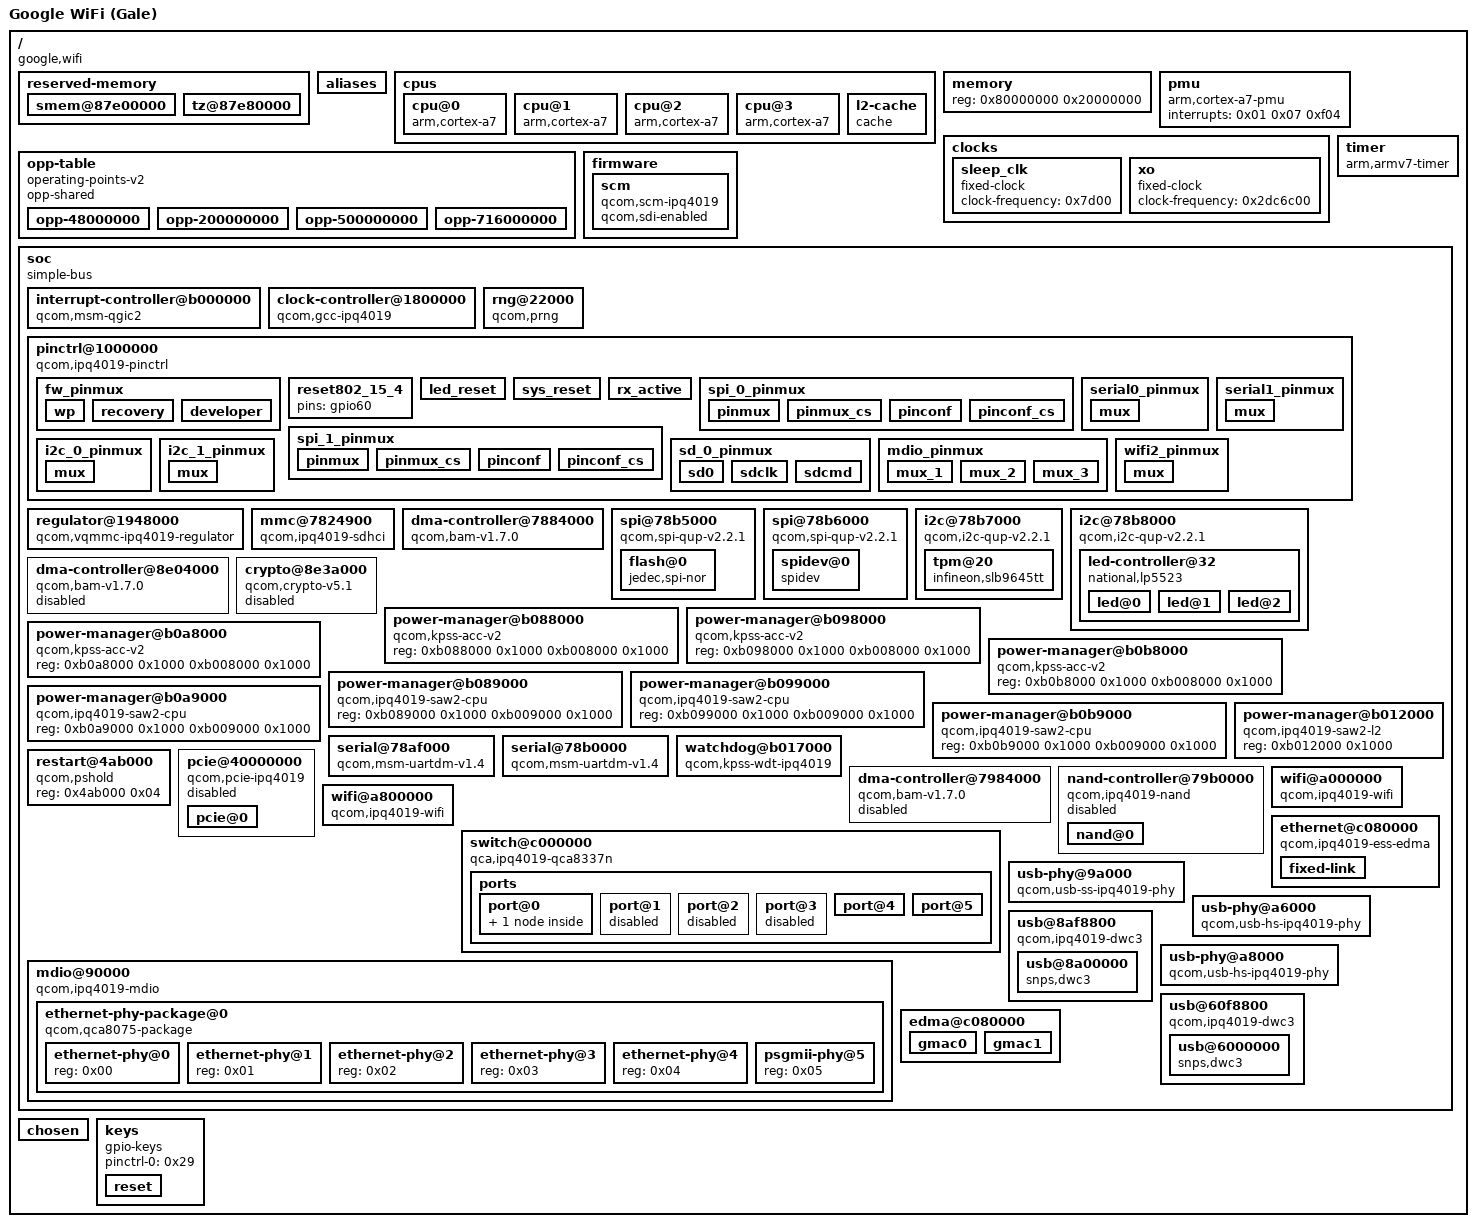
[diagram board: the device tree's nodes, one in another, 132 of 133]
/dts-v1/;

/ {
	#address-cells = <0x01>;
	#size-cells = <0x01>;
	model = "Google WiFi (Gale)";
	compatible = "google,wifi\0google,gale-v2\0qcom,ipq4019";
	interrupt-parent = <0x01>;

	reserved-memory {
		#address-cells = <0x01>;
		#size-cells = <0x01>;
		ranges;

		smem@87e00000 {
			reg = <0x87e00000 0x80000>;
			no-map;
		};

		tz@87e80000 {
			reg = <0x87e80000 0x180000>;
			no-map;
		};
	};

	aliases {
		spi0 = "/soc/spi@78b5000";
		spi1 = "/soc/spi@78b6000";
		i2c0 = "/soc/i2c@78b7000";
		i2c1 = "/soc/i2c@78b8000";
		ethernet0 = "/soc/ethernet@c080000";
		label-mac-device = "/soc/edma@c080000/gmac0";
		led-boot = "/soc/i2c@78b8000/led-controller@32/led@2";
		led-failsafe = "/soc/i2c@78b8000/led-controller@32/led@0";
		led-running = "/soc/i2c@78b8000/led-controller@32/led@2";
		led-upgrade = "/soc/i2c@78b8000/led-controller@32/led@0";
	};

	cpus {
		#address-cells = <0x01>;
		#size-cells = <0x00>;

		cpu@0 {
			device_type = "cpu";
			compatible = "arm,cortex-a7";
			enable-method = "qcom,kpss-acc-v2";
			next-level-cache = <0x02>;
			qcom,acc = <0x03>;
			qcom,saw = <0x04>;
			reg = <0x00>;
			clocks = <0x05 0x09>;
			clock-frequency = <0x00>;
			clock-latency = <0x3e800>;
			operating-points-v2 = <0x06>;
		};

		cpu@1 {
			device_type = "cpu";
			compatible = "arm,cortex-a7";
			enable-method = "qcom,kpss-acc-v2";
			next-level-cache = <0x02>;
			qcom,acc = <0x07>;
			qcom,saw = <0x08>;
			reg = <0x01>;
			clocks = <0x05 0x09>;
			clock-frequency = <0x00>;
			clock-latency = <0x3e800>;
			operating-points-v2 = <0x06>;
		};

		cpu@2 {
			device_type = "cpu";
			compatible = "arm,cortex-a7";
			enable-method = "qcom,kpss-acc-v2";
			next-level-cache = <0x02>;
			qcom,acc = <0x09>;
			qcom,saw = <0x0a>;
			reg = <0x02>;
			clocks = <0x05 0x09>;
			clock-frequency = <0x00>;
			clock-latency = <0x3e800>;
			operating-points-v2 = <0x06>;
		};

		cpu@3 {
			device_type = "cpu";
			compatible = "arm,cortex-a7";
			enable-method = "qcom,kpss-acc-v2";
			next-level-cache = <0x02>;
			qcom,acc = <0x0b>;
			qcom,saw = <0x0c>;
			reg = <0x03>;
			clocks = <0x05 0x09>;
			clock-frequency = <0x00>;
			clock-latency = <0x3e800>;
			operating-points-v2 = <0x06>;
		};

		l2-cache {
			compatible = "cache";
			cache-level = <0x02>;
			cache-unified;
			qcom,saw = <0x0d>;
			phandle = <0x02>;
		};
	};

	opp-table {
		compatible = "operating-points-v2";
		opp-shared;
		phandle = <0x06>;

		opp-48000000 {
			opp-hz = <0x00 0x2dc6c00>;
			clock-latency-ns = <0x3e800>;
		};

		opp-200000000 {
			opp-hz = <0x00 0xbebc200>;
			clock-latency-ns = <0x3e800>;
		};

		opp-500000000 {
			opp-hz = <0x00 0x1dcd6500>;
			clock-latency-ns = <0x3e800>;
		};

		opp-716000000 {
			opp-hz = <0x00 0x2aad4b00>;
			clock-latency-ns = <0x3e800>;
		};
	};

	memory {
		device_type = "memory";
		reg = <0x80000000 0x20000000>;
	};

	pmu {
		compatible = "arm,cortex-a7-pmu";
		interrupts = <0x01 0x07 0xf04>;
	};

	clocks {

		sleep_clk {
			compatible = "fixed-clock";
			clock-frequency = <0x7d00>;
			#clock-cells = <0x00>;
			phandle = <0x0f>;
		};

		xo {
			compatible = "fixed-clock";
			clock-frequency = <0x2dc6c00>;
			#clock-cells = <0x00>;
			phandle = <0x0e>;
		};
	};

	firmware {

		scm {
			compatible = "qcom,scm-ipq4019\0qcom,scm";
			qcom,sdi-enabled;
		};
	};

	timer {
		compatible = "arm,armv7-timer";
		interrupts = <0x01 0x02 0xf08 0x01 0x03 0xf08 0x01 0x04 0xf08 0x01 0x01 0xf08>;
		clock-frequency = <0x2dc6c00>;
		always-on;
	};

	soc {
		#address-cells = <0x01>;
		#size-cells = <0x01>;
		ranges;
		compatible = "simple-bus";

		interrupt-controller@b000000 {
			compatible = "qcom,msm-qgic2";
			interrupt-controller;
			#interrupt-cells = <0x03>;
			reg = <0xb000000 0x1000 0xb002000 0x1000>;
			phandle = <0x01>;
		};

		clock-controller@1800000 {
			compatible = "qcom,gcc-ipq4019";
			#clock-cells = <0x01>;
			#reset-cells = <0x01>;
			reg = <0x1800000 0x60000>;
			clocks = <0x0e 0x0f>;
			clock-names = "xo\0sleep_clk";
			phandle = <0x05>;
		};

		rng@22000 {
			compatible = "qcom,prng";
			reg = <0x22000 0x140>;
			clocks = <0x05 0x2b>;
			clock-names = "core";
			status = "okay";
		};

		pinctrl@1000000 {
			compatible = "qcom,ipq4019-pinctrl";
			reg = <0x1000000 0x300000>;
			gpio-controller;
			gpio-ranges = <0x10 0x00 0x00 0x64>;
			#gpio-cells = <0x02>;
			interrupt-controller;
			#interrupt-cells = <0x02>;
			interrupts = <0x00 0xd0 0x04>;
			gpio-line-names = <0x00 0x00 0x00 0x00 0x00 0x00 0x00 0x00 0x00 0x00 0x00 0x00 0x00 0x41505f 0x464c4153 0x485f5750 0x5f4c0000 0x5245 0x434f5645 0x52595f53 0x575f4c00>;
			phandle = <0x10>;

			fw_pinmux {
				phandle = <0x29>;

				wp {
					pins = "gpio53";
					output-low;
				};

				recovery {
					pins = "gpio57";
					function = "gpio";
					bias-none;
				};

				developer {
					pins = "gpio41";
					bias-none;
				};
			};

			reset802_15_4 {
				pins = "gpio60";
			};

			led_reset {
				pins = "gpio22";
				output-high;
			};

			sys_reset {
				pins = "gpio19";
				output-high;
			};

			rx_active {
				pins = "gpio43";
				bias-pull,down;
			};

			spi_0_pinmux {
				phandle = <0x14>;

				pinmux {
					function = "blsp_spi0";
					pins = "gpio13\0gpio14\0gpio15";
				};

				pinmux_cs {
					function = "gpio";
					pins = "gpio12";
				};

				pinconf {
					pins = "gpio13\0gpio14\0gpio15";
					drive-strength = <0x0c>;
					bias-disable;
				};

				pinconf_cs {
					pins = "gpio12";
					drive-strength = <0x02>;
					bias-disable;
					output-high;
				};
			};

			spi_1_pinmux {
				phandle = <0x15>;

				pinmux {
					function = "blsp_spi1";
					pins = "gpio44\0gpio46\0gpio47";
				};

				pinmux_cs {
					function = "gpio";
					pins = "gpio45";
				};

				pinconf {
					pins = "gpio44\0gpio46\0gpio47";
					drive-strength = <0x0c>;
					bias-disable;
				};

				pinconf_cs {
					pins = "gpio45";
					drive-strength = <0x02>;
					bias-disable;
					output-high;
				};
			};

			serial0_pinmux {
				phandle = <0x19>;

				mux {
					pins = "gpio16\0gpio17";
					function = "blsp_uart0";
					bias-disable;
				};
			};

			serial1_pinmux {
				phandle = <0x1a>;

				mux {
					pins = "gpio8\0gpio9\0gpio10\0gpio11";
					function = "blsp_uart1";
					bias-disable;
				};
			};

			i2c_0_pinmux {
				phandle = <0x16>;

				mux {
					pins = "gpio20\0gpio21";
					function = "blsp_i2c0";
					drive-open-drain;
				};
			};

			i2c_1_pinmux {
				phandle = <0x17>;

				mux {
					pins = "gpio34\0gpio35";
					function = "blsp_i2c1";
					drive-open-drain;
				};
			};

			sd_0_pinmux {
				phandle = <0x11>;

				sd0 {
					pins = "gpio23\0gpio24\0gpio25\0gpio26\0gpio29\0gpio30\0gpio31\0gpio32";
					function = "sdio";
					drive-strength = <0x0a>;
					bias-pull-up;
					pull-up-res = <0x00>;
				};

				sdclk {
					pins = "gpio27";
					function = "sdio";
					drive-strength = <0x02>;
					bias-pull-up;
					pull-up-res = <0x00>;
				};

				sdcmd {
					pins = "gpio28";
					function = "sdio";
					drive-strength = <0x0a>;
					bias-pull-up;
					pull-up-res = <0x00>;
				};
			};

			mdio_pinmux {
				phandle = <0x25>;

				mux_1 {
					pins = "gpio6";
					function = "mdio";
					bias-disable;
				};

				mux_2 {
					pins = "gpio7";
					function = "mdc";
					bias-disable;
				};

				mux_3 {
					pins = "gpio40";
					function = "gpio";
					bias-disable;
					output-high;
				};
			};

			wifi2_pinmux {
				phandle = <0x1c>;

				mux {
					pins = "gpio58";
					output-low;
				};
			};
		};

		regulator@1948000 {
			compatible = "qcom,vqmmc-ipq4019-regulator";
			reg = <0x1948000 0x04>;
			regulator-name = "vqmmc";
			regulator-min-microvolt = <0x16e360>;
			regulator-max-microvolt = <0x2dc6c0>;
			regulator-always-on;
			status = "okay";
			phandle = <0x12>;
		};

		mmc@7824900 {
			compatible = "qcom,ipq4019-sdhci\0qcom,sdhci-msm-v4";
			reg = <0x7824900 0x11c 0x7824000 0x800>;
			reg-names = "hc\0core";
			interrupts = <0x00 0x7b 0x04 0x00 0x8a 0x04>;
			interrupt-names = "hc_irq\0pwr_irq";
			bus-width = <0x08>;
			clocks = <0x05 0x2e 0x05 0x2f 0x0e>;
			clock-names = "iface\0core\0xo";
			status = "okay";
			pinctrl-0 = <0x11>;
			pinctrl-names = "default";
			clock-frequency = <0xb71b000>;
			vqmmc-supply = <0x12>;
			non-removable;
		};

		dma-controller@7884000 {
			compatible = "qcom,bam-v1.7.0";
			reg = <0x7884000 0x23000>;
			interrupts = <0x00 0xee 0x04>;
			clocks = <0x05 0x15>;
			clock-names = "bam_clk";
			#dma-cells = <0x01>;
			qcom,ee = <0x00>;
			status = "okay";
			phandle = <0x13>;
		};

		spi@78b5000 {
			compatible = "qcom,spi-qup-v2.2.1";
			reg = <0x78b5000 0x600>;
			interrupts = <0x00 0x5f 0x04>;
			clocks = <0x05 0x17 0x05 0x15>;
			clock-names = "core\0iface";
			#address-cells = <0x01>;
			#size-cells = <0x00>;
			dmas = <0x13 0x04 0x13 0x05>;
			dma-names = "tx\0rx";
			status = "okay";
			pinctrl-0 = <0x14>;
			pinctrl-names = "default";
			cs-gpios = <0x10 0x0c 0x01>;

			flash@0 {
				compatible = "jedec,spi-nor";
				reg = <0x00>;
				spi-max-frequency = <0x16e3600>;
			};
		};

		spi@78b6000 {
			compatible = "qcom,spi-qup-v2.2.1";
			reg = <0x78b6000 0x600>;
			interrupts = <0x00 0x60 0x04>;
			clocks = <0x05 0x19 0x05 0x15>;
			clock-names = "core\0iface";
			#address-cells = <0x01>;
			#size-cells = <0x00>;
			dmas = <0x13 0x06 0x13 0x07>;
			dma-names = "tx\0rx";
			status = "okay";
			pinctrl-0 = <0x15>;
			pinctrl-names = "default";
			cs-gpios = <0x10 0x2d 0x01>;

			spidev@0 {
				compatible = "spidev";
				reg = <0x00>;
				spi-max-frequency = <0x16e3600>;
			};
		};

		i2c@78b7000 {
			compatible = "qcom,i2c-qup-v2.2.1";
			reg = <0x78b7000 0x600>;
			interrupts = <0x00 0x61 0x04>;
			clocks = <0x05 0x16 0x05 0x15>;
			clock-names = "core\0iface";
			#address-cells = <0x01>;
			#size-cells = <0x00>;
			dmas = <0x13 0x08 0x13 0x09>;
			dma-names = "tx\0rx";
			status = "okay";
			pinctrl-0 = <0x16>;
			pinctrl-names = "default";

			tpm@20 {
				compatible = "infineon,slb9645tt";
				reg = <0x20>;
				powered-while-suspended;
			};
		};

		i2c@78b8000 {
			compatible = "qcom,i2c-qup-v2.2.1";
			reg = <0x78b8000 0x600>;
			interrupts = <0x00 0x62 0x04>;
			clocks = <0x05 0x18 0x05 0x15>;
			clock-names = "core\0iface";
			#address-cells = <0x01>;
			#size-cells = <0x00>;
			dmas = <0x13 0x0a 0x13 0x0b>;
			dma-names = "tx\0rx";
			status = "okay";
			pinctrl-0 = <0x17>;
			pinctrl-names = "default";

			led-controller@32 {
				#address-cells = <0x01>;
				#size-cells = <0x00>;
				compatible = "national,lp5523";
				reg = <0x32>;
				clock-mode = [01];

				led@0 {
					reg = <0x00>;
					chan-name = "LED0_Red";
					led-cur = [64];
					max-cur = [78];
					color = <0x01>;
					function = "fault";
				};

				led@1 {
					reg = <0x01>;
					chan-name = "LED0_Green";
					led-cur = [64];
					max-cur = [78];
					color = <0x02>;
				};

				led@2 {
					reg = <0x02>;
					chan-name = "LED0_Blue";
					led-cur = [64];
					max-cur = [78];
					color = <0x03>;
					function = "power";
				};
			};
		};

		dma-controller@8e04000 {
			compatible = "qcom,bam-v1.7.0";
			reg = <0x8e04000 0x20000>;
			interrupts = <0x00 0xcf 0x04>;
			clocks = <0x05 0x21>;
			clock-names = "bam_clk";
			#dma-cells = <0x01>;
			qcom,ee = <0x01>;
			qcom,controlled-remotely;
			status = "disabled";
			phandle = <0x18>;
		};

		crypto@8e3a000 {
			compatible = "qcom,crypto-v5.1";
			reg = <0x8e3a000 0x6000>;
			clocks = <0x05 0x21 0x05 0x22 0x05 0x23>;
			clock-names = "iface\0bus\0core";
			dmas = <0x18 0x02 0x18 0x03>;
			dma-names = "rx\0tx";
			status = "disabled";
		};

		power-manager@b088000 {
			compatible = "qcom,kpss-acc-v2";
			reg = <0xb088000 0x1000 0xb008000 0x1000>;
			phandle = <0x03>;
		};

		power-manager@b098000 {
			compatible = "qcom,kpss-acc-v2";
			reg = <0xb098000 0x1000 0xb008000 0x1000>;
			phandle = <0x07>;
		};

		power-manager@b0a8000 {
			compatible = "qcom,kpss-acc-v2";
			reg = <0xb0a8000 0x1000 0xb008000 0x1000>;
			phandle = <0x09>;
		};

		power-manager@b0b8000 {
			compatible = "qcom,kpss-acc-v2";
			reg = <0xb0b8000 0x1000 0xb008000 0x1000>;
			phandle = <0x0b>;
		};

		power-manager@b089000 {
			compatible = "qcom,ipq4019-saw2-cpu\0qcom,saw2";
			reg = <0xb089000 0x1000 0xb009000 0x1000>;
			phandle = <0x04>;
		};

		power-manager@b099000 {
			compatible = "qcom,ipq4019-saw2-cpu\0qcom,saw2";
			reg = <0xb099000 0x1000 0xb009000 0x1000>;
			phandle = <0x08>;
		};

		power-manager@b0a9000 {
			compatible = "qcom,ipq4019-saw2-cpu\0qcom,saw2";
			reg = <0xb0a9000 0x1000 0xb009000 0x1000>;
			phandle = <0x0a>;
		};

		power-manager@b0b9000 {
			compatible = "qcom,ipq4019-saw2-cpu\0qcom,saw2";
			reg = <0xb0b9000 0x1000 0xb009000 0x1000>;
			phandle = <0x0c>;
		};

		power-manager@b012000 {
			compatible = "qcom,ipq4019-saw2-l2\0qcom,saw2";
			reg = <0xb012000 0x1000>;
			phandle = <0x0d>;
		};

		serial@78af000 {
			compatible = "qcom,msm-uartdm-v1.4\0qcom,msm-uartdm";
			reg = <0x78af000 0x200>;
			interrupts = <0x00 0x6b 0x04>;
			status = "okay";
			clocks = <0x05 0x1a 0x05 0x15>;
			clock-names = "core\0iface";
			dmas = <0x13 0x00 0x13 0x01>;
			dma-names = "tx\0rx";
			pinctrl-0 = <0x19>;
			pinctrl-names = "default";
		};

		serial@78b0000 {
			compatible = "qcom,msm-uartdm-v1.4\0qcom,msm-uartdm";
			reg = <0x78b0000 0x200>;
			interrupts = <0x00 0x6c 0x04>;
			status = "okay";
			clocks = <0x05 0x1b 0x05 0x15>;
			clock-names = "core\0iface";
			dmas = <0x13 0x02 0x13 0x03>;
			dma-names = "tx\0rx";
			pinctrl-0 = <0x1a>;
			pinctrl-names = "default";
		};

		watchdog@b017000 {
			compatible = "qcom,kpss-wdt-ipq4019\0qcom,kpss-wdt";
			reg = <0xb017000 0x40>;
			clocks = <0x0f>;
			timeout-sec = <0x0a>;
			status = "okay";
		};

		restart@4ab000 {
			compatible = "qcom,pshold";
			reg = <0x4ab000 0x04>;
		};

		pcie@40000000 {
			compatible = "qcom,pcie-ipq4019";
			reg = <0x40000000 0xf1d 0x40000f20 0xa8 0x80000 0x2000 0x40100000 0x1000>;
			reg-names = "dbi\0elbi\0parf\0config";
			device_type = "pci";
			linux,pci-domain = <0x00>;
			bus-range = <0x00 0xff>;
			num-lanes = <0x01>;
			#address-cells = <0x03>;
			#size-cells = <0x02>;
			ranges = <0x81000000 0x00 0x00 0x40200000 0x00 0x100000 0x82000000 0x00 0x40300000 0x40300000 0x00 0xd00000>;
			interrupts = <0x00 0x8d 0x04>;
			interrupt-names = "msi";
			#interrupt-cells = <0x01>;
			interrupt-map-mask = <0x00 0x00 0x00 0x07>;
			interrupt-map = <0x00 0x00 0x00 0x01 0x01 0x00 0x8e 0x04 0x00 0x00 0x00 0x02 0x01 0x00 0x8f 0x04 0x00 0x00 0x00 0x03 0x01 0x00 0x90 0x04 0x00 0x00 0x00 0x04 0x01 0x00 0x91 0x04>;
			clocks = <0x05 0x27 0x05 0x28 0x05 0x29>;
			clock-names = "aux\0master_bus\0slave_bus";
			resets = <0x05 0x1c 0x05 0x1b 0x05 0x1a 0x05 0x19 0x05 0x18 0x05 0x17 0x05 0x16 0x05 0x15 0x05 0x14 0x05 0x13 0x05 0x12 0x05 0x11>;
			reset-names = "axi_m\0axi_s\0pipe\0axi_m_vmid\0axi_s_xpu\0parf\0phy\0axi_m_sticky\0pipe_sticky\0pwr\0ahb\0phy_ahb";
			status = "disabled";

			pcie@0 {
				device_type = "pci";
				reg = <0x00 0x00 0x00 0x00 0x00>;
				bus-range = <0x01 0xff>;
				#address-cells = <0x03>;
				#size-cells = <0x02>;
				ranges;
			};
		};

		dma-controller@7984000 {
			compatible = "qcom,bam-v1.7.0";
			reg = <0x7984000 0x1a000>;
			interrupts = <0x00 0x65 0x04>;
			clocks = <0x05 0x2d>;
			clock-names = "bam_clk";
			#dma-cells = <0x01>;
			qcom,ee = <0x00>;
			status = "disabled";
			phandle = <0x1b>;
		};

		nand-controller@79b0000 {
			compatible = "qcom,ipq4019-nand";
			reg = <0x79b0000 0x1000>;
			#address-cells = <0x01>;
			#size-cells = <0x00>;
			clocks = <0x05 0x2d 0x05 0x2c>;
			clock-names = "core\0aon";
			dmas = <0x1b 0x00 0x1b 0x01 0x1b 0x02>;
			dma-names = "tx\0rx\0cmd";
			status = "disabled";

			nand@0 {
				reg = <0x00>;
				nand-ecc-strength = <0x04>;
				nand-ecc-step-size = <0x200>;
				nand-bus-width = <0x08>;
			};
		};

		wifi@a000000 {
			compatible = "qcom,ipq4019-wifi";
			reg = <0xa000000 0x200000>;
			resets = <0x05 0x00 0x05 0x01 0x05 0x02 0x05 0x03 0x05 0x04 0x05 0x05>;
			reset-names = "wifi_cpu_init\0wifi_radio_srif\0wifi_radio_warm\0wifi_radio_cold\0wifi_core_warm\0wifi_core_cold";
			clocks = <0x05 0x3b 0x05 0x3c 0x05 0x3d>;
			clock-names = "wifi_wcss_cmd\0wifi_wcss_ref\0wifi_wcss_rtc";
			interrupts = <0x00 0x20 0x01 0x00 0x21 0x01 0x00 0x22 0x01 0x00 0x23 0x01 0x00 0x24 0x01 0x00 0x25 0x01 0x00 0x26 0x01 0x00 0x27 0x01 0x00 0x28 0x01 0x00 0x29 0x01 0x00 0x2a 0x01 0x00 0x2b 0x01 0x00 0x2c 0x01 0x00 0x2d 0x01 0x00 0x2e 0x01 0x00 0x2f 0x01 0x00 0xa8 0x04>;
			interrupt-names = "msi0\0msi1\0msi2\0msi3\0msi4\0msi5\0msi6\0msi7\0msi8\0msi9\0msi10\0msi11\0msi12\0msi13\0msi14\0msi15\0legacy";
			status = "okay";
			qcom,ath10k-calibration-variant = "GO_GALE";
		};

		wifi@a800000 {
			compatible = "qcom,ipq4019-wifi";
			reg = <0xa800000 0x200000>;
			resets = <0x05 0x06 0x05 0x07 0x05 0x08 0x05 0x09 0x05 0x0a 0x05 0x0b>;
			reset-names = "wifi_cpu_init\0wifi_radio_srif\0wifi_radio_warm\0wifi_radio_cold\0wifi_core_warm\0wifi_core_cold";
			clocks = <0x05 0x3e 0x05 0x3f 0x05 0x40>;
			clock-names = "wifi_wcss_cmd\0wifi_wcss_ref\0wifi_wcss_rtc";
			interrupts = <0x00 0x30 0x01 0x00 0x31 0x01 0x00 0x32 0x01 0x00 0x33 0x01 0x00 0x34 0x01 0x00 0x35 0x01 0x00 0x36 0x01 0x00 0x37 0x01 0x00 0x38 0x01 0x00 0x39 0x01 0x00 0x3a 0x01 0x00 0x3b 0x01 0x00 0x3c 0x01 0x00 0x3d 0x01 0x00 0x3e 0x01 0x00 0x3f 0x01 0x00 0xa9 0x04>;
			interrupt-names = "msi0\0msi1\0msi2\0msi3\0msi4\0msi5\0msi6\0msi7\0msi8\0msi9\0msi10\0msi11\0msi12\0msi13\0msi14\0msi15\0legacy";
			status = "okay";
			pinctrl-0 = <0x1c>;
			pinctrl-names = "default";
			qcom,ath10k-calibration-variant = "GO_GALE";
		};

		switch@c000000 {
			compatible = "qca,ipq4019-qca8337n";
			reg = <0xc000000 0x80000 0x98000 0x800>;
			reg-names = "base\0psgmii_phy";
			resets = <0x05 0x4d>;
			reset-names = "psgmii_rst";
			mdio = <0x1d>;
			psgmii-ethphy = <0x1e>;
			status = "okay";

			ports {
				#address-cells = <0x01>;
				#size-cells = <0x00>;

				port@0 {
					reg = <0x00>;
					label = "cpu";
					ethernet = <0x1f>;
					phy-mode = "internal";

					fixed-link {
						speed = <0x3e8>;
						full-duplex;
						pause;
						asym-pause;
					};
				};

				port@1 {
					reg = <0x01>;
					label = "lan1";
					phy-handle = <0x20>;
					phy-mode = "psgmii";
					status = "disabled";
				};

				port@2 {
					reg = <0x02>;
					label = "lan2";
					phy-handle = <0x21>;
					phy-mode = "psgmii";
					status = "disabled";
				};

				port@3 {
					reg = <0x03>;
					label = "lan3";
					phy-handle = <0x22>;
					phy-mode = "psgmii";
					status = "disabled";
				};

				port@4 {
					reg = <0x04>;
					label = "lan";
					phy-handle = <0x23>;
					phy-mode = "psgmii";
					status = "okay";
				};

				port@5 {
					reg = <0x05>;
					label = "wan";
					phy-handle = <0x24>;
					phy-mode = "psgmii";
					status = "okay";
				};
			};
		};

		ethernet@c080000 {
			compatible = "qcom,ipq4019-ess-edma";
			reg = <0xc080000 0x8000>;
			resets = <0x05 0x1d>;
			reset-names = "ess";
			clocks = <0x05 0x24>;
			clock-names = "ess";
			interrupts = <0x00 0x41 0x01 0x00 0x42 0x01 0x00 0x43 0x01 0x00 0x44 0x01 0x00 0x45 0x01 0x00 0x46 0x01 0x00 0x47 0x01 0x00 0x48 0x01 0x00 0x49 0x01 0x00 0x4a 0x01 0x00 0x4b 0x01 0x00 0x4c 0x01 0x00 0x4d 0x01 0x00 0x4e 0x01 0x00 0x4f 0x01 0x00 0x50 0x01 0x00 0xf0 0x01 0x00 0xf1 0x01 0x00 0xf2 0x01 0x00 0xf3 0x01 0x00 0xf4 0x01 0x00 0xf5 0x01 0x00 0xf6 0x01 0x00 0xf7 0x01 0x00 0xf8 0x01 0x00 0xf9 0x01 0x00 0xfa 0x01 0x00 0xfb 0x01 0x00 0xfc 0x01 0x00 0xfd 0x01 0x00 0xfe 0x01 0x00 0xff 0x01>;
			phy-mode = "internal";
			status = "okay";
			phandle = <0x1f>;

			fixed-link {
				speed = <0x3e8>;
				full-duplex;
				pause;
			};
		};

		mdio@90000 {
			#address-cells = <0x01>;
			#size-cells = <0x00>;
			compatible = "qcom,ipq4019-mdio";
			reg = <0x90000 0x64>;
			status = "okay";
			pinctrl-0 = <0x25>;
			pinctrl-names = "default";
			phandle = <0x1d>;

			ethernet-phy-package@0 {
				#address-cells = <0x01>;
				#size-cells = <0x00>;
				compatible = "qcom,qca8075-package";
				reg = <0x00>;
				qcom,tx-drive-strength-milliwatt = <0x12c>;

				ethernet-phy@0 {
					reg = <0x00>;
					phandle = <0x20>;
				};

				ethernet-phy@1 {
					reg = <0x01>;
					phandle = <0x21>;
				};

				ethernet-phy@2 {
					reg = <0x02>;
					phandle = <0x22>;
				};

				ethernet-phy@3 {
					reg = <0x03>;
					phandle = <0x23>;
				};

				ethernet-phy@4 {
					reg = <0x04>;
					phandle = <0x24>;
				};

				psgmii-phy@5 {
					reg = <0x05>;
					phandle = <0x1e>;
				};
			};
		};

		usb-phy@9a000 {
			compatible = "qcom,usb-ss-ipq4019-phy";
			#phy-cells = <0x00>;
			reg = <0x9a000 0x800>;
			reg-names = "phy_base";
			resets = <0x05 0x0c>;
			reset-names = "por_rst";
			status = "okay";
			phandle = <0x27>;
		};

		usb-phy@a6000 {
			compatible = "qcom,usb-hs-ipq4019-phy";
			#phy-cells = <0x00>;
			reg = <0xa6000 0x40>;
			reg-names = "phy_base";
			resets = <0x05 0x0d 0x05 0x0e>;
			reset-names = "por_rst\0srif_rst";
			status = "okay";
			phandle = <0x26>;
		};

		usb@8af8800 {
			compatible = "qcom,ipq4019-dwc3\0qcom,dwc3";
			reg = <0x8af8800 0x100>;
			#address-cells = <0x01>;
			#size-cells = <0x01>;
			clocks = <0x05 0x38 0x05 0x39 0x05 0x3a>;
			clock-names = "core\0sleep\0mock_utmi";
			ranges;
			status = "okay";

			usb@8a00000 {
				compatible = "snps,dwc3";
				reg = <0x8a00000 0xf8000>;
				interrupts = <0x00 0x84 0x04>;
				phys = <0x26 0x27>;
				phy-names = "usb2-phy\0usb3-phy";
				dr_mode = "host";
			};
		};

		usb-phy@a8000 {
			compatible = "qcom,usb-hs-ipq4019-phy";
			#phy-cells = <0x00>;
			reg = <0xa8000 0x40>;
			reg-names = "phy_base";
			resets = <0x05 0x0f 0x05 0x10>;
			reset-names = "por_rst\0srif_rst";
			status = "okay";
			phandle = <0x28>;
		};

		usb@60f8800 {
			compatible = "qcom,ipq4019-dwc3\0qcom,dwc3";
			reg = <0x60f8800 0x100>;
			#address-cells = <0x01>;
			#size-cells = <0x01>;
			clocks = <0x05 0x35 0x05 0x36 0x05 0x37>;
			clock-names = "core\0sleep\0mock_utmi";
			ranges;
			status = "okay";

			usb@6000000 {
				compatible = "snps,dwc3";
				reg = <0x6000000 0xf8000>;
				interrupts = <0x00 0x88 0x04>;
				phys = <0x28>;
				phy-names = "usb2-phy";
				dr_mode = "host";
			};
		};

		edma@c080000 {

			gmac0 {
			};

			gmac1 {
			};
		};
	};

	chosen {
		bootargs-append = " rootwait";
		stdout-path = "/soc/serial@78af000";
	};

	keys {
		compatible = "gpio-keys";
		pinctrl-0 = <0x29>;
		pinctrl-names = "default";

		reset {
			label = "reset";
			gpios = <0x10 0x39 0x01>;
			linux,code = <0x198>;
		};
	};
};
